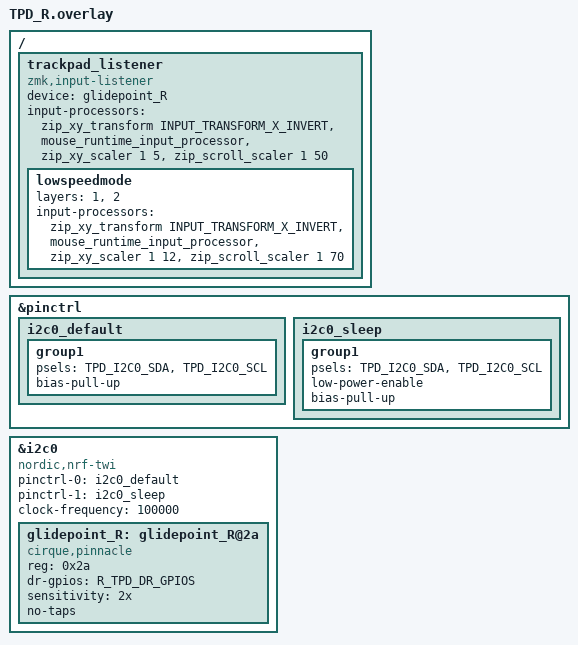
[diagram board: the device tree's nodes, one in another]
#include <dt-bindings/zmk/keys.h>
#include <dt-bindings/zmk/pointing.h>

&pinctrl {
    i2c0_default: i2c0_default {
        group1 {
            psels = <TPD_I2C0_SDA>,
                    <TPD_I2C0_SCL>;
            bias-pull-up;
        };
    };

    i2c0_sleep: i2c0_sleep {
        group1 {
            psels = <TPD_I2C0_SDA>,
                    <TPD_I2C0_SCL>;
            low-power-enable;
            bias-pull-up;
        };
    };
};

&i2c0 {
    status = "okay";
    compatible = "nordic,nrf-twi";
    pinctrl-0 = <&i2c0_default>;
    pinctrl-1 = <&i2c0_sleep>;
    pinctrl-names = "default", "sleep";
    clock-frequency = <100000>;

    glidepoint_R: glidepoint_R@2a {
        compatible = "cirque,pinnacle";
        reg = <0x2a>;
        status = "okay";
        dr-gpios = R_TPD_DR_GPIOS;
        sensitivity = "2x";
        no-taps;
    };
};

/ {
    trackpad_listener: trackpad_listener {
        compatible = "zmk,input-listener";
        status = "okay";
        device = <&glidepoint_R>;

        input-processors = <&zip_xy_transform INPUT_TRANSFORM_X_INVERT>,
                           <&mouse_runtime_input_processor>,
                           <&zip_xy_scaler 1 5>,
                           <&zip_scroll_scaler 1 50>;

        lowspeedmode {
            layers = <1>, <2>;
            input-processors = <&zip_xy_transform INPUT_TRANSFORM_X_INVERT>,
                               <&mouse_runtime_input_processor>,
                               <&zip_xy_scaler 1 12>,
                               <&zip_scroll_scaler 1 70>;
        };
    };
};
